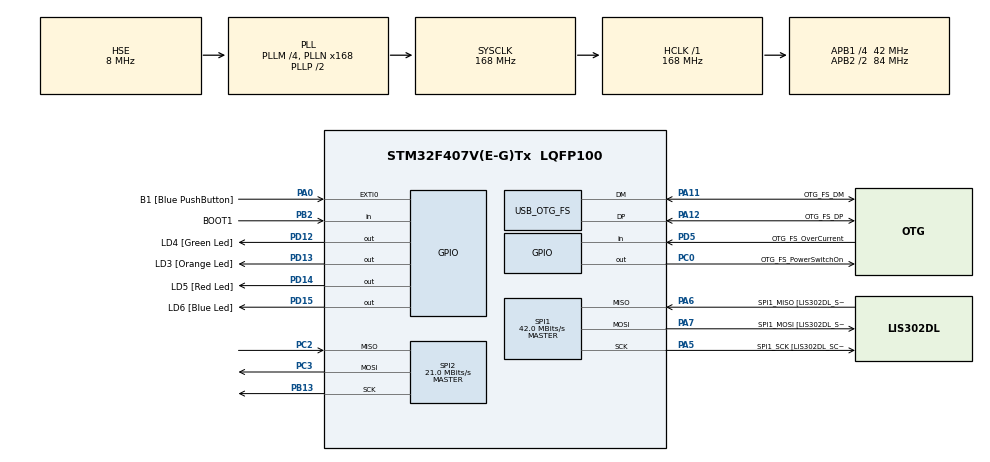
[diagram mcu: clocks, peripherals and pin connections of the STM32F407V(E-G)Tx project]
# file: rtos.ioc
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FREERTOS.Tasks01=defaultTask,0,128,StartDefaultTask,Default,NULL
Mcu.Family=STM32F4
Mcu.Name=STM32F407V(E-G)Tx
Mcu.Package=LQFP100
NVIC.OTG_FS_IRQn=true\:5\:0\:false\:false\:true\:true
NVIC.PriorityGroup=NVIC_PRIORITYGROUP_4
NVIC.TIM7_IRQn=true\:0\:0\:false\:false\:true\:false
NVIC.TimeBase=TIM7_IRQn
NVIC.TimeBaseIP=TIM7
PA0-WKUP.GPIO_Label=B1 [Blue PushButton]
PA0-WKUP.GPIO_ModeDefaultEXTI=GPIO_MODE_EVT_RISING
PA0-WKUP.GPIO_PuPd=GPIO_NOPULL
PA0-WKUP.Signal=GPXTI0
PA11.GPIO_Label=OTG_FS_DM
PA11.GPIO_Mode=GPIO_MODE_AF_PP
PA11.GPIO_PuPd=GPIO_NOPULL
PA11.GPIO_Speed=GPIO_SPEED_FREQ_LOW
PA11.Mode=Device_Only
PA11.Signal=USB_OTG_FS_DM
PA12.GPIO_Label=OTG_FS_DP
PA12.GPIO_Mode=GPIO_MODE_AF_PP
PA12.GPIO_PuPd=GPIO_NOPULL
PA12.GPIO_Speed=GPIO_SPEED_FREQ_LOW
PA12.Mode=Device_Only
PA12.Signal=USB_OTG_FS_DP
PA13.GPIO_Label=SWDIO
PA13.Mode=Serial_Wire
PA13.Signal=SYS_JTMS-SWDIO
PA14.GPIO_Label=SWCLK
PA14.Mode=Serial_Wire
PA14.Signal=SYS_JTCK-SWCLK
PA5.GPIO_Label=SPI1_SCK [LIS302DL_SCL/SPC]
PA5.GPIO_Mode=GPIO_MODE_AF_PP
PA5.GPIO_PuPd=GPIO_NOPULL
PA5.GPIO_Speed=GPIO_SPEED_FREQ_LOW
PA5.Mode=Full_Duplex_Master
PA5.Signal=SPI1_SCK
PA6.GPIO_Label=SPI1_MISO [LIS302DL_SDO]
PA6.GPIO_Mode=GPIO_MODE_AF_PP
PA6.GPIO_PuPd=GPIO_NOPULL
PA6.GPIO_Speed=GPIO_SPEED_FREQ_LOW
PA6.Mode=Full_Duplex_Master
PA6.Signal=SPI1_MISO
PA7.GPIO_Label=SPI1_MOSI [LIS302DL_SDA/SDI/SDO]
PA7.GPIO_Mode=GPIO_MODE_AF_PP
PA7.GPIO_PuPd=GPIO_NOPULL
PA7.GPIO_Speed=GPIO_SPEED_FREQ_LOW
PA7.Mode=Full_Duplex_Master
PA7.Signal=SPI1_MOSI
PB13.Mode=Full_Duplex_Master
PB13.Signal=SPI2_SCK
PB2.GPIO_Label=BOOT1
PB2.GPIO_Mode=GPIO_MODE_INPUT
PB2.GPIO_PuPd=GPIO_NOPULL
PB2.Signal=GPIO_Input
PC0.GPIO_Label=OTG_FS_PowerSwitchOn
PC0.GPIO_PuPd=GPIO_NOPULL
PC0.GPIO_Speed=GPIO_SPEED_FREQ_LOW
PC0.PinState=GPIO_PIN_SET
PC0.Signal=GPIO_Output
PC2.Mode=Full_Duplex_Master
PC2.Signal=SPI2_MISO
PC3.Mode=Full_Duplex_Master
PC3.Signal=SPI2_MOSI
PD12.GPIO_Label=LD4 [Green Led]
PD12.GPIO_PuPd=GPIO_NOPULL
PD12.GPIO_Speed=GPIO_SPEED_FREQ_LOW
PD12.Signal=GPIO_Output
PD13.GPIO_Label=LD3 [Orange Led]
PD13.GPIO_PuPd=GPIO_NOPULL
PD13.GPIO_Speed=GPIO_SPEED_FREQ_LOW
PD13.Signal=GPIO_Output
PD14.GPIO_Label=LD5 [Red Led]
PD14.GPIO_PuPd=GPIO_NOPULL
PD14.GPIO_Speed=GPIO_SPEED_FREQ_LOW
PD14.Signal=GPIO_Output
PD15.GPIO_Label=LD6 [Blue Led]
PD15.GPIO_PuPd=GPIO_NOPULL
PD15.GPIO_Speed=GPIO_SPEED_FREQ_LOW
PD15.Signal=GPIO_Output
PD5.GPIO_Label=OTG_FS_OverCurrent
PD5.GPIO_Mode=GPIO_MODE_INPUT
PD5.GPIO_PuPd=GPIO_NOPULL
PD5.Signal=GPIO_Input
PH0-OSC_IN.GPIO_Label=PH0-OSC_IN
PH0-OSC_IN.Mode=HSE-External-Clock-Source
PH0-OSC_IN.Signal=RCC_OSC_IN
PH1-OSC_OUT.GPIO_Label=PH1-OSC_OUT
PH1-OSC_OUT.Mode=HSE-External-Clock-Source
PH1-OSC_OUT.Signal=RCC_OSC_OUT
ProjectManager.HeapSize=0x200
ProjectManager.StackSize=0x400
ProjectManager.TargetToolchain=SW4STM32
RCC.48MHZClocksFreq_Value=48000000
RCC.AHBFreq_Value=168000000
RCC.APB1CLKDivider=RCC_HCLK_DIV4
RCC.APB1Freq_Value=42000000
RCC.APB1TimFreq_Value=84000000
RCC.APB2CLKDivider=RCC_HCLK_DIV2
RCC.APB2Freq_Value=84000000
RCC.APB2TimFreq_Value=168000000
RCC.CortexFreq_Value=168000000
RCC.HCLKFreq_Value=168000000
RCC.HSE_VALUE=8000000
RCC.HSI_VALUE=16000000
RCC.LSE_VALUE=32768
RCC.PLLM=4
RCC.PLLN=168
RCC.PLLQ=7
RCC.SYSCLKFreq_VALUE=168000000
RCC.SYSCLKSource=RCC_SYSCLKSOURCE_PLLCLK
RCC.VCOOutputFreq_Value=336000000
SPI1.CalculateBaudRate=42.0 MBits/s
SPI1.Direction=SPI_DIRECTION_2LINES
SPI1.Mode=SPI_MODE_MASTER
SPI1.VirtualType=VM_MASTER
SPI2.CalculateBaudRate=21.0 MBits/s
SPI2.Direction=SPI_DIRECTION_2LINES
SPI2.Mode=SPI_MODE_MASTER
SPI2.VirtualType=VM_MASTER
USB_DEVICE.CLASS_NAME_FS=CDC
USB_DEVICE.VirtualModeFS=Cdc_FS
USB_OTG_FS.VirtualMode=Device_Only
VP_FREERTOS_VS_ENABLE.Mode=Enabled
VP_SYS_VS_tim7.Mode=TIM7
VP_TIM6_VS_ClockSourceINT.Mode=Enable_Timer
VP_USB_DEVICE_VS_USB_DEVICE_CDC_FS.Mode=CDC_FS
board=STM32F4DISCOVERY

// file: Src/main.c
/**
  ******************************************************************************
  * File Name          : main.c
  * Description        : Main program body
  ******************************************************************************
  * This notice applies to any and all portions of this file
  * that are not between comment pairs USER CODE BEGIN and
  * USER CODE END. Other portions of this file, whether
  * inserted by the user or by software development tools
  * are owned by their respective copyright owners.
  *
  * Copyright (c) 2017 STMicroelectronics International N.V.
  * All rights reserved.
  *
  * Redistribution and use in source and binary forms, with or without
  * modification, are permitted, provided that the following conditions are met:
  *
  * 1. Redistribution of source code must retain the above copyright notice,
  *    this list of conditions and the following disclaimer.
  * 2. Redistributions in binary form must reproduce the above copyright notice,
  *    this list of conditions and the following disclaimer in the documentation
  *    and/or other materials provided with the distribution.
  * 3. Neither the name of STMicroelectronics nor the names of other
  *    contributors to this software may be used to endorse or promote products
  *    derived from this software without specific written permission.
  * 4. This software, including modifications and/or derivative works of this
  *    software, must execute solely and exclusively on microcontroller or
  *    microprocessor devices manufactured by or for STMicroelectronics.
  * 5. Redistribution and use of this software other than as permitted under
  *    this license is void and will automatically terminate your rights under
  *    this license.
  *
  * THIS SOFTWARE IS PROVIDED BY STMICROELECTRONICS AND CONTRIBUTORS "AS IS"
  * AND ANY EXPRESS, IMPLIED OR STATUTORY WARRANTIES, INCLUDING, BUT NOT
  * LIMITED TO, THE IMPLIED WARRANTIES OF MERCHANTABILITY, FITNESS FOR A
  * PARTICULAR PURPOSE AND NON-INFRINGEMENT OF THIRD PARTY INTELLECTUAL PROPERTY
  * RIGHTS ARE DISCLAIMED TO THE FULLEST EXTENT PERMITTED BY LAW. IN NO EVENT
  * SHALL STMICROELECTRONICS OR CONTRIBUTORS BE LIABLE FOR ANY DIRECT, INDIRECT,
  * INCIDENTAL, SPECIAL, EXEMPLARY, OR CONSEQUENTIAL DAMAGES (INCLUDING, BUT NOT
  * LIMITED TO, PROCUREMENT OF SUBSTITUTE GOODS OR SERVICES; LOSS OF USE, DATA,
  * OR PROFITS; OR BUSINESS INTERRUPTION) HOWEVER CAUSED AND ON ANY THEORY OF
  * LIABILITY, WHETHER IN CONTRACT, STRICT LIABILITY, OR TORT (INCLUDING
  * NEGLIGENCE OR OTHERWISE) ARISING IN ANY WAY OUT OF THE USE OF THIS SOFTWARE,
  * EVEN IF ADVISED OF THE POSSIBILITY OF SUCH DAMAGE.
  *
  ******************************************************************************
  */
#include "main.h"
#include "stm32f4xx_hal.h"
#include "cmsis_os.h"
#include "usb_device.h"

SPI_HandleTypeDef hspi1;
SPI_HandleTypeDef hspi2;

TIM_HandleTypeDef htim6;

osThreadId defaultTaskHandle;

/* USER CODE BEGIN PV */
/* Private variables ---------------------------------------------------------*/
int user;

/* USER CODE END PV */

void SystemClock_Config(void);
static void MX_GPIO_Init(void);
static void MX_TIM6_Init(void);
static void MX_SPI1_Init(void);
static void MX_SPI2_Init(void);
void StartDefaultTask(void const * argument);

/* USER CODE BEGIN PFP */
/* Private function prototypes -----------------------------------------------*/

/* USER CODE END PFP */

int main(void)
{

  /* MCU Configuration----------------------------------------------------------*/

  /* Reset of all peripherals, Initializes the Flash interface and the Systick. */
  HAL_Init();

  /* Configure the system clock */
  SystemClock_Config();

  /* Initialize all configured peripherals */
  MX_GPIO_Init();
  MX_TIM6_Init();
  MX_SPI1_Init();
  MX_SPI2_Init();

  /* Create the thread(s) */
  /* definition and creation of defaultTask */
  osThreadDef(defaultTask, StartDefaultTask, osPriorityNormal, 0, 128);
  defaultTaskHandle = osThreadCreate(osThread(defaultTask), NULL);

  /* Start scheduler */
  osKernelStart();

  /* We should never get here as control is now taken by the scheduler */

  /* Infinite loop */
  while (1)
  {

  }

}

/** System Clock Configuration
*/
void SystemClock_Config(void)
{

  RCC_OscInitTypeDef RCC_OscInitStruct;
  RCC_ClkInitTypeDef RCC_ClkInitStruct;

    /**Configure the main internal regulator output voltage
    */
  __HAL_RCC_PWR_CLK_ENABLE();

  __HAL_PWR_VOLTAGESCALING_CONFIG(PWR_REGULATOR_VOLTAGE_SCALE1);

    /**Initializes the CPU, AHB and APB busses clocks
    */
  RCC_OscInitStruct.OscillatorType = RCC_OSCILLATORTYPE_HSE;
  RCC_OscInitStruct.HSEState = RCC_HSE_BYPASS;
  RCC_OscInitStruct.PLL.PLLState = RCC_PLL_ON;
  RCC_OscInitStruct.PLL.PLLSource = RCC_PLLSOURCE_HSE;
  RCC_OscInitStruct.PLL.PLLM = 4;
  RCC_OscInitStruct.PLL.PLLN = 168;
  RCC_OscInitStruct.PLL.PLLP = RCC_PLLP_DIV2;
  RCC_OscInitStruct.PLL.PLLQ = 7;
  if (HAL_RCC_OscConfig(&RCC_OscInitStruct) != HAL_OK)
  {
    _Error_Handler(__FILE__, __LINE__);
  }

    /**Initializes the CPU, AHB and APB busses clocks
    */
  RCC_ClkInitStruct.ClockType = RCC_CLOCKTYPE_HCLK|RCC_CLOCKTYPE_SYSCLK
                              |RCC_CLOCKTYPE_PCLK1|RCC_CLOCKTYPE_PCLK2;
  RCC_ClkInitStruct.SYSCLKSource = RCC_SYSCLKSOURCE_PLLCLK;
  RCC_ClkInitStruct.AHBCLKDivider = RCC_SYSCLK_DIV1;
  RCC_ClkInitStruct.APB1CLKDivider = RCC_HCLK_DIV4;
  RCC_ClkInitStruct.APB2CLKDivider = RCC_HCLK_DIV2;

  if (HAL_RCC_ClockConfig(&RCC_ClkInitStruct, FLASH_LATENCY_5) != HAL_OK)
  {
    _Error_Handler(__FILE__, __LINE__);
  }

    /**Configure the Systick interrupt time
    */
  HAL_SYSTICK_Config(HAL_RCC_GetHCLKFreq()/1000);

    /**Configure the Systick
    */
  HAL_SYSTICK_CLKSourceConfig(SYSTICK_CLKSOURCE_HCLK);

  /* SysTick_IRQn interrupt configuration */
  HAL_NVIC_SetPriority(SysTick_IRQn, 15, 0);
}

/* SPI1 init function */
static void MX_SPI1_Init(void)
{

  hspi1.Instance = SPI1;
  hspi1.Init.Mode = SPI_MODE_MASTER;
  hspi1.Init.Direction = SPI_DIRECTION_2LINES;
  hspi1.Init.DataSize = SPI_DATASIZE_8BIT;
  hspi1.Init.CLKPolarity = SPI_POLARITY_LOW;
  hspi1.Init.CLKPhase = SPI_PHASE_1EDGE;
  hspi1.Init.NSS = SPI_NSS_SOFT;
  hspi1.Init.BaudRatePrescaler = SPI_BAUDRATEPRESCALER_2;
  hspi1.Init.FirstBit = SPI_FIRSTBIT_MSB;
  hspi1.Init.TIMode = SPI_TIMODE_DISABLE;
  hspi1.Init.CRCCalculation = SPI_CRCCALCULATION_DISABLE;
  hspi1.Init.CRCPolynomial = 10;
  if (HAL_SPI_Init(&hspi1) != HAL_OK)
  {
    _Error_Handler(__FILE__, __LINE__);
  }

}

/* SPI2 init function */
static void MX_SPI2_Init(void)
{

  hspi2.Instance = SPI2;
  hspi2.Init.Mode = SPI_MODE_MASTER;
  hspi2.Init.Direction = SPI_DIRECTION_2LINES;
  hspi2.Init.DataSize = SPI_DATASIZE_8BIT;
  hspi2.Init.CLKPolarity = SPI_POLARITY_LOW;
  hspi2.Init.CLKPhase = SPI_PHASE_1EDGE;
  hspi2.Init.NSS = SPI_NSS_SOFT;
  hspi2.Init.BaudRatePrescaler = SPI_BAUDRATEPRESCALER_2;
  hspi2.Init.FirstBit = SPI_FIRSTBIT_MSB;
  hspi2.Init.TIMode = SPI_TIMODE_DISABLE;
  hspi2.Init.CRCCalculation = SPI_CRCCALCULATION_DISABLE;
  hspi2.Init.CRCPolynomial = 10;
  if (HAL_SPI_Init(&hspi2) != HAL_OK)
  {
    _Error_Handler(__FILE__, __LINE__);
  }

}

/* TIM6 init function */
static void MX_TIM6_Init(void)
{

  TIM_MasterConfigTypeDef sMasterConfig;

  htim6.Instance = TIM6;
  htim6.Init.Prescaler = 0;
  htim6.Init.CounterMode = TIM_COUNTERMODE_UP;
  htim6.Init.Period = 0;
  if (HAL_TIM_Base_Init(&htim6) != HAL_OK)
  {
    _Error_Handler(__FILE__, __LINE__);
  }

  sMasterConfig.MasterOutputTrigger = TIM_TRGO_RESET;
  sMasterConfig.MasterSlaveMode = TIM_MASTERSLAVEMODE_DISABLE;
  if (HAL_TIMEx_MasterConfigSynchronization(&htim6, &sMasterConfig) != HAL_OK)
  {
    _Error_Handler(__FILE__, __LINE__);
  }

}

/** Configure pins as
        * Analog
        * Input
        * Output
        * EVENT_OUT
        * EXTI
*/
static void MX_GPIO_Init(void)
{

  GPIO_InitTypeDef GPIO_InitStruct;

  /* GPIO Ports Clock Enable */
  __HAL_RCC_GPIOH_CLK_ENABLE();
  __HAL_RCC_GPIOC_CLK_ENABLE();
  __HAL_RCC_GPIOA_CLK_ENABLE();
  __HAL_RCC_GPIOB_CLK_ENABLE();
  __HAL_RCC_GPIOD_CLK_ENABLE();

  /*Configure GPIO pin Output Level */
  HAL_GPIO_WritePin(OTG_FS_PowerSwitchOn_GPIO_Port, OTG_FS_PowerSwitchOn_Pin, GPIO_PIN_SET);

  /*Configure GPIO pin Output Level */
  HAL_GPIO_WritePin(GPIOD, LD4_Pin|LD3_Pin|LD5_Pin|LD6_Pin, GPIO_PIN_RESET);

  /*Configure GPIO pin : OTG_FS_PowerSwitchOn_Pin */
  GPIO_InitStruct.Pin = OTG_FS_PowerSwitchOn_Pin;
  GPIO_InitStruct.Mode = GPIO_MODE_OUTPUT_PP;
  GPIO_InitStruct.Pull = GPIO_NOPULL;
  GPIO_InitStruct.Speed = GPIO_SPEED_FREQ_LOW;
  HAL_GPIO_Init(OTG_FS_PowerSwitchOn_GPIO_Port, &GPIO_InitStruct);

  /*Configure GPIO pin : B1_Pin */
  GPIO_InitStruct.Pin = B1_Pin;
  GPIO_InitStruct.Mode = GPIO_MODE_EVT_RISING;
  GPIO_InitStruct.Pull = GPIO_NOPULL;
  HAL_GPIO_Init(B1_GPIO_Port, &GPIO_InitStruct);

  /*Configure GPIO pin : BOOT1_Pin */
  GPIO_InitStruct.Pin = BOOT1_Pin;
  GPIO_InitStruct.Mode = GPIO_MODE_INPUT;
  GPIO_InitStruct.Pull = GPIO_NOPULL;
  HAL_GPIO_Init(BOOT1_GPIO_Port, &GPIO_InitStruct);

  /*Configure GPIO pins : LD4_Pin LD3_Pin LD5_Pin LD6_Pin */
  GPIO_InitStruct.Pin = LD4_Pin|LD3_Pin|LD5_Pin|LD6_Pin;
  GPIO_InitStruct.Mode = GPIO_MODE_OUTPUT_PP;
  GPIO_InitStruct.Pull = GPIO_NOPULL;
  GPIO_InitStruct.Speed = GPIO_SPEED_FREQ_LOW;
  HAL_GPIO_Init(GPIOD, &GPIO_InitStruct);

  /*Configure GPIO pin : OTG_FS_OverCurrent_Pin */
  GPIO_InitStruct.Pin = OTG_FS_OverCurrent_Pin;
  GPIO_InitStruct.Mode = GPIO_MODE_INPUT;
  GPIO_InitStruct.Pull = GPIO_NOPULL;
  HAL_GPIO_Init(OTG_FS_OverCurrent_GPIO_Port, &GPIO_InitStruct);

}

/* StartDefaultTask function */
void StartDefaultTask(void const * argument)
{
  /* init code for USB_DEVICE */
  MX_USB_DEVICE_Init();

  for(;;)
  {
    osDelay(1);
  }
}

void HAL_TIM_PeriodElapsedCallback(TIM_HandleTypeDef *htim)
{
  if (htim->Instance == TIM7) {
    HAL_IncTick();
  }
}

void _Error_Handler(char * file, int line)
{
  while(1)
  {
  }
}

/************************ (C) COPYRIGHT STMicroelectronics *****END OF FILE****/
